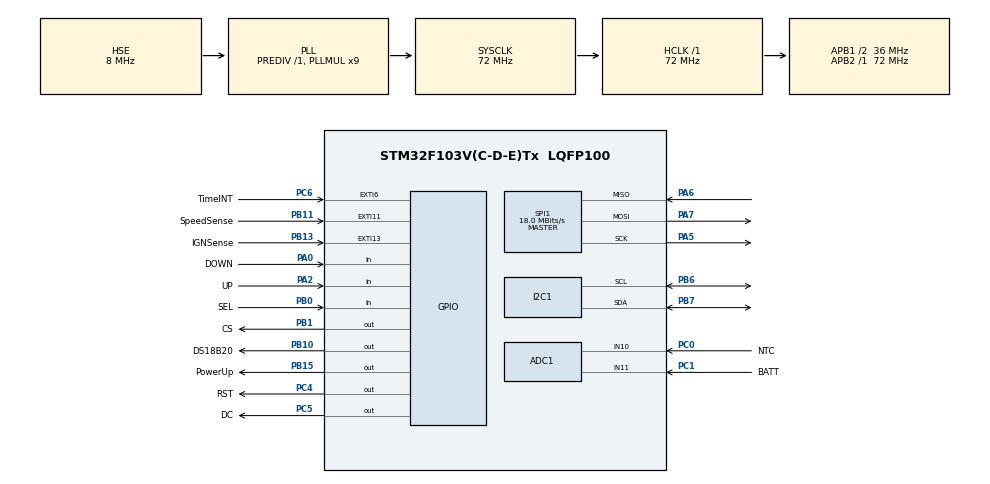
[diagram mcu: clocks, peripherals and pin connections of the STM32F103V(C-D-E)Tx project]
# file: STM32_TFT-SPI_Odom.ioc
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ADC1.Channel-0\#ChannelRegularConversion=ADC_CHANNEL_10
ADC1.Channel-1\#ChannelRegularConversion=ADC_CHANNEL_11
ADC1.NbrOfConversion=2
ADC1.NbrOfConversionFlag=1
ADC1.Rank-0\#ChannelRegularConversion=1
ADC1.Rank-1\#ChannelRegularConversion=2
ADC1.SamplingTime-0\#ChannelRegularConversion=ADC_SAMPLETIME_71CYCLES_5
ADC1.SamplingTime-1\#ChannelRegularConversion=ADC_SAMPLETIME_71CYCLES_5
ADC1.master=1
Mcu.Family=STM32F1
Mcu.Name=STM32F103V(C-D-E)Tx
Mcu.Package=LQFP100
NVIC.EXTI15_10_IRQn=true\:0\:0\:false\:false\:true\:true\:true\:true
NVIC.EXTI9_5_IRQn=true\:0\:0\:false\:false\:true\:true\:true\:true
NVIC.PriorityGroup=NVIC_PRIORITYGROUP_4
OSC_IN.Mode=HSE-External-Oscillator
OSC_IN.Signal=RCC_OSC_IN
OSC_OUT.Mode=HSE-External-Oscillator
OSC_OUT.Signal=RCC_OSC_OUT
PA0-WKUP.GPIO_Label=DOWN
PA0-WKUP.GPIO_PuPd=GPIO_PULLUP
PA0-WKUP.Signal=GPIO_Input
PA2.GPIO_Label=UP
PA2.GPIO_PuPd=GPIO_PULLUP
PA2.Signal=GPIO_Input
PA5.Mode=Full_Duplex_Master
PA5.Signal=SPI1_SCK
PA6.Mode=Full_Duplex_Master
PA6.Signal=SPI1_MISO
PA7.Mode=Full_Duplex_Master
PA7.Signal=SPI1_MOSI
PB0.GPIO_Label=SEL
PB0.GPIO_PuPd=GPIO_PULLUP
PB0.Signal=GPIO_Input
PB1.GPIO_Label=CS
PB1.GPIO_PuPd=GPIO_PULLUP
PB1.Signal=GPIO_Output
PB10.GPIO_Label=DS18B20
PB10.GPIO_ModeDefaultOutputPP=GPIO_MODE_OUTPUT_OD
PB10.GPIO_PuPd=GPIO_NOPULL
PB10.Signal=GPIO_Output
PB11.GPIO_Label=SpeedSense
PB11.GPIO_ModeDefaultEXTI=GPIO_MODE_IT_FALLING
PB11.GPIO_PuPd=GPIO_PULLUP
PB11.Signal=GPXTI11
PB13.GPIO_Label=IGNSense
PB13.GPIO_ModeDefaultEXTI=GPIO_MODE_IT_FALLING
PB13.GPIO_PuPd=GPIO_PULLUP
PB13.Signal=GPXTI13
PB15.GPIO_Label=PowerUp
PB15.Signal=GPIO_Output
PB6.Mode=I2C
PB6.Signal=I2C1_SCL
PB7.Mode=I2C
PB7.Signal=I2C1_SDA
PC0.GPIO_Label=NTC
PC0.Signal=ADCx_IN10
PC1.GPIO_Label=BATT
PC1.Signal=ADCx_IN11
PC4.GPIO_Label=RST
PC4.GPIO_PuPd=GPIO_PULLUP
PC4.Signal=GPIO_Output
PC5.GPIO_Label=DC
PC5.GPIO_PuPd=GPIO_PULLUP
PC5.Signal=GPIO_Output
PC6.GPIO_Label=TimeINT
PC6.GPIO_ModeDefaultEXTI=GPIO_MODE_IT_FALLING
PC6.Signal=GPXTI6
ProjectManager.HeapSize=0x200
ProjectManager.StackSize=0x400
ProjectManager.TargetToolchain=STM32CubeIDE
RCC.ADCPresc=RCC_ADCPCLK2_DIV6
RCC.AHBFreq_Value=72000000
RCC.APB1CLKDivider=RCC_HCLK_DIV2
RCC.APB1Freq_Value=36000000
RCC.APB1TimFreq_Value=72000000
RCC.APB2Freq_Value=72000000
RCC.APB2TimFreq_Value=72000000
RCC.HCLKFreq_Value=72000000
RCC.PLLMUL=RCC_PLL_MUL9
RCC.PLLSourceVirtual=RCC_PLLSOURCE_HSE
RCC.SYSCLKFreq_VALUE=72000000
RCC.SYSCLKSource=RCC_SYSCLKSOURCE_PLLCLK
RCC.USBFreq_Value=72000000
SH.ADCx_IN10.0=ADC1_IN10,IN10
SH.ADCx_IN11.0=ADC1_IN11,IN11
SPI1.BaudRatePrescaler=SPI_BAUDRATEPRESCALER_4
SPI1.CalculateBaudRate=18.0 MBits/s
SPI1.Direction=SPI_DIRECTION_2LINES
SPI1.Mode=SPI_MODE_MASTER
SPI1.VirtualType=VM_MASTER
VP_SYS_VS_ND.Mode=No_Debug
board=custom

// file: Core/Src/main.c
/* USER CODE BEGIN Header */
/**
  ******************************************************************************
  * @file           : main.c
  * @brief          : Main program body
  ******************************************************************************
  * @attention
  *
  * Copyright (c) 2026 STMicroelectronics.
  * All rights reserved.
  *
  * This software is licensed under terms that can be found in the LICENSE file
  * in the root directory of this software component.
  * If no LICENSE file comes with this software, it is provided AS-IS.
  *
  ******************************************************************************
  */
/* USER CODE END Header */
#include "main.h"
#include "adc.h"
#include "i2c.h"
#include "spi.h"
#include "gpio.h"
//#include "../../ui/ui.h"

void SystemClock_Config(void);

int main(void)
{

  /* MCU Configuration--------------------------------------------------------*/

  /* Reset of all peripherals, Initializes the Flash interface and the Systick. */
  HAL_Init();

  /* Configure the system clock */
  SystemClock_Config();

  /* Initialize all configured peripherals */
  MX_GPIO_Init();
  MX_ADC1_Init();
  MX_I2C1_Init();
  MX_SPI1_Init();
  /* USER CODE BEGIN 2 */

  lcd_init();

  lcd_fill_screen(0xF800);
  //ui_init();
  ui_draw_static_test();
  /* USER CODE END 2 */

  /* Infinite loop */
  while (1)
  {

  }
}

void SystemClock_Config(void)
{
  RCC_OscInitTypeDef RCC_OscInitStruct = {0};
  RCC_ClkInitTypeDef RCC_ClkInitStruct = {0};
  RCC_PeriphCLKInitTypeDef PeriphClkInit = {0};

  /** Initializes the RCC Oscillators according to the specified parameters
  * in the RCC_OscInitTypeDef structure.
  */
  RCC_OscInitStruct.OscillatorType = RCC_OSCILLATORTYPE_HSE;
  RCC_OscInitStruct.HSEState = RCC_HSE_ON;
  RCC_OscInitStruct.HSEPredivValue = RCC_HSE_PREDIV_DIV1;
  RCC_OscInitStruct.HSIState = RCC_HSI_ON;
  RCC_OscInitStruct.PLL.PLLState = RCC_PLL_ON;
  RCC_OscInitStruct.PLL.PLLSource = RCC_PLLSOURCE_HSE;
  RCC_OscInitStruct.PLL.PLLMUL = RCC_PLL_MUL9;
  if (HAL_RCC_OscConfig(&RCC_OscInitStruct) != HAL_OK)
  {
    Error_Handler();
  }

  /** Initializes the CPU, AHB and APB buses clocks
  */
  RCC_ClkInitStruct.ClockType = RCC_CLOCKTYPE_HCLK|RCC_CLOCKTYPE_SYSCLK
                              |RCC_CLOCKTYPE_PCLK1|RCC_CLOCKTYPE_PCLK2;
  RCC_ClkInitStruct.SYSCLKSource = RCC_SYSCLKSOURCE_PLLCLK;
  RCC_ClkInitStruct.AHBCLKDivider = RCC_SYSCLK_DIV1;
  RCC_ClkInitStruct.APB1CLKDivider = RCC_HCLK_DIV2;
  RCC_ClkInitStruct.APB2CLKDivider = RCC_HCLK_DIV1;

  if (HAL_RCC_ClockConfig(&RCC_ClkInitStruct, FLASH_LATENCY_2) != HAL_OK)
  {
    Error_Handler();
  }
  PeriphClkInit.PeriphClockSelection = RCC_PERIPHCLK_ADC;
  PeriphClkInit.AdcClockSelection = RCC_ADCPCLK2_DIV6;
  if (HAL_RCCEx_PeriphCLKConfig(&PeriphClkInit) != HAL_OK)
  {
    Error_Handler();
  }
}

void Error_Handler(void)
{
  __disable_irq();
  while (1)
  {
  }
}
